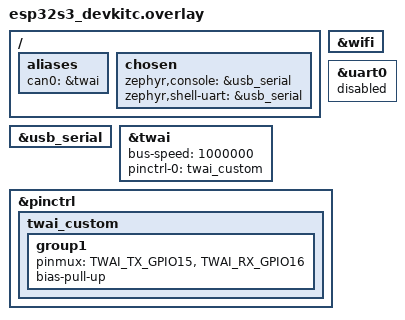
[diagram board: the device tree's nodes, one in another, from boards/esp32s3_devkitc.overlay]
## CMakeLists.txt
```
cmake_minimum_required(VERSION 3.20.0)

find_package(Zephyr REQUIRED HINTS $ENV{ZEPHYR_BASE})
project(can_dongle)

if(EXISTS "${CMAKE_CURRENT_SOURCE_DIR}/src/wifi_secrets.h")
  target_compile_definitions(app PRIVATE DONGLE_USE_LOCAL_WIFI_SECRETS=1)
endif()

target_sources(app PRIVATE
  src/main.c
  src/command_handler.c
  src/command_policy.c
  src/motor_status_policy.c
  src/telemetry.c
  src/telemetry_policy.c
  src/sdo_transport.c
  src/udp_comm.c
  src/can_raw.c
  src/canopen_basic.c
  src/json_protocol.c
  src/watchdog.c
)
```

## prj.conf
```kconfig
# ---- Early Console (调试必需) ----
CONFIG_EARLY_CONSOLE=y
CONFIG_CONSOLE=y
CONFIG_UART_CONSOLE=y

# ---- Wi-Fi + Networking ----
CONFIG_WIFI=y
CONFIG_WIFI_LOG_LEVEL_DBG=n
CONFIG_NETWORKING=y
CONFIG_NET_L2_ETHERNET=y
CONFIG_NET_UDP=y
CONFIG_NET_SOCKETS=y
CONFIG_NET_IPV4=y
CONFIG_NET_IPV6=n
CONFIG_NET_CONFIG_AUTO_INIT=n

# ---- DHCP Server (AP 模式下给客户端分配 IP) ----
CONFIG_NET_DHCPV4_SERVER=y
CONFIG_NET_DHCPV4_SERVER_LOG_LEVEL_DBG=n

# ---- CAN ----
CONFIG_CAN=y
# CONFIG_CAN_AUTO_BUS_OFF_RECOVERY removed in Zephyr 4.4

# ---- Logging ----
CONFIG_LOG=y
CONFIG_LOG_DEFAULT_LEVEL=3
CONFIG_LOG_PRINTK=y

# ---- JSON support ----
CONFIG_JSON_LIBRARY=y

# ---- Memory ----
CONFIG_MAIN_STACK_SIZE=8192
CONFIG_HEAP_MEM_POOL_SIZE=65536

# ---- Shell (debug only, disable for production) ----
CONFIG_SHELL=n

# ---- Assert ----
CONFIG_ASSERT=y

# ---- Explicit main-thread scheduling ----
CONFIG_MAIN_THREAD_PRIORITY=5
CONFIG_SYSTEM_WORKQUEUE_PRIORITY=1
```

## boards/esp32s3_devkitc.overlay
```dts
/ {
	aliases {
		can0 = &twai;
	};

	chosen {
		zephyr,console = &usb_serial;
		zephyr,shell-uart = &usb_serial;
	};
};

&wifi {
	status = "okay";
};

&usb_serial {
	status = "okay";
};

&uart0 {
	status = "disabled";
};

&twai {
	status = "okay";
	bus-speed = <1000000>;
	/* TX=GPIO15 确认可用, RX=GPIO16 + 内部上拉 */
	pinctrl-0 = <&twai_custom>;
	pinctrl-names = "default";
};

&pinctrl {
	twai_custom: twai_custom {
		group1 {
			pinmux = <TWAI_TX_GPIO15>,
				 <TWAI_RX_GPIO16>;
			bias-pull-up;
		};
	};
};
```

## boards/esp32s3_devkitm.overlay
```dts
/ {
	aliases {
		can0 = &twai;
	};

	chosen {
		zephyr,console = &usb_serial;
		zephyr,shell-uart = &usb_serial;
	};
};

&wifi {
	status = "okay";
};

&usb_serial {
	status = "okay";
};

&uart0 {
	status = "disabled";
};

&twai {
	status = "okay";
	bus-speed = <1000000>;
	pinctrl-0 = <&twai_default>;
	pinctrl-names = "default";
};
```

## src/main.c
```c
#include <zephyr/kernel.h>
#include <zephyr/logging/log.h>

#include "udp_comm.h"
#include "can_raw.h"
#include "json_protocol.h"
#include "watchdog.h"
#include "motor_state.h"
#include "command_handler.h"
#include "telemetry.h"
#include "sdo_transport.h"

LOG_MODULE_REGISTER(main, LOG_LEVEL_INF);

#define MAIN_LOOP_DELAY_MS 10
#define UDP_RECEIVE_TIMEOUT_MS 10
#define MAX_UDP_MESSAGES_PER_LOOP 16
#define MAX_CAN_FRAMES_PER_LOOP 8

struct motor_state g_motor = {
	.drive_status_word = 0x0040,
	.mode = MODE_PROFILE_VELOCITY,
};
bool g_motor_enabled;
bool g_profile_configured;
int32_t g_target_speed = 50000;
uint8_t g_active_node = DEFAULT_NODE;

static void forward_can_frames(void)
{
	can_frame_t frame;
	char buffer[256];
	for (int count = 0;
	     count < MAX_CAN_FRAMES_PER_LOOP && can_recv(&frame) == 1;
	     count++) {
		int length = json_build_can_log(buffer, sizeof(buffer),
						frame.id, frame.data, frame.dlc);
		udp_send(buffer, length);
	}
}

static void handle_udp_messages(char *buffer, int buffer_size)
{
	int timeout_ms = UDP_RECEIVE_TIMEOUT_MS;

	for (int count = 0; count < MAX_UDP_MESSAGES_PER_LOOP; count++) {
		int length = udp_recv(buffer, buffer_size, timeout_ms);
		if (length <= 0) break;

		parsed_cmd_t command;
		if (cmd_json_parse(buffer, length, &command))
			command_handle(&command);

		timeout_ms = 0;
	}
}

int main(void)
{
	wdg_init();
	int ret = udp_init();
	if (ret < 0) LOG_ERR("UDP init failed: %d", ret);
	ret = can_init();
	if (ret < 0) LOG_WRN("CAN init failed: %d", ret);
	else can_diag();

	char receive_buffer[2048];
	while (1) {
		handle_udp_messages(receive_buffer, sizeof(receive_buffer));
		if (wdg_check())
			command_handle_watchdog_timeout();
		forward_can_frames();
		telemetry_send();
		k_msleep(MAIN_LOOP_DELAY_MS);
	}
	return 0;
}
```

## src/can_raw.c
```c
/*
 * can_raw.c - CAN 原始帧收发模块实现
 *
 * 使用 Zephyr CAN 驱动。硬件假设:
 *   - ESP32-S3 内部 TWAI 控制器
 *   - 外部 TJA1050 收发器
 *   - RX: GPIO16, TX: GPIO15 (在 overlay 中定义)
 */

#include "can_raw.h"

#include <stdio.h>
#include <string.h>
#include <zephyr/kernel.h>
#include <zephyr/device.h>
#include <zephyr/drivers/can.h>
#include <zephyr/logging/log.h>

LOG_MODULE_REGISTER(can_raw, LOG_LEVEL_INF);

/* ---- 配置 ---- */
#define CAN_BAUDRATE		1000000

/* ---- 消息队列: 缓冲接收到的 CAN 帧 ---- */
CAN_MSGQ_DEFINE(can_rx_msgq, 16);

/* ---- 状态 ---- */
static const struct device *can_dev = NULL;
static bool initialized = false;
static int rx_filter_id = -1;
static K_SEM_DEFINE(tx_done_sem, 0, 1);
static int tx_done_error;

static void log_can_state(const char *where)
{
	enum can_state state;
	struct can_bus_err_cnt err_cnt;
	int ret;

	if (!can_dev) {
		return;
	}

	ret = can_get_state(can_dev, &state, &err_cnt);
	if (ret < 0) {
		LOG_WRN("%s: failed to get CAN state: %d", where, ret);
		return;
	}

	LOG_WRN("%s: CAN state=%d tx_err=%u rx_err=%u",
		where, state, err_cnt.tx_err_cnt, err_cnt.rx_err_cnt);
}

static int can_restart_if_needed(const char *where)
{
	enum can_state state;
	struct can_bus_err_cnt err_cnt;
	int ret;

	if (!can_dev) {
		return -ENODEV;
	}

	ret = can_get_state(can_dev, &state, &err_cnt);
	if (ret < 0) {
		return ret;
	}

	if (state != CAN_STATE_ERROR_PASSIVE &&
	    state != CAN_STATE_BUS_OFF &&
	    state != CAN_STATE_STOPPED) {
		return 0;
	}

	LOG_WRN("%s: restarting CAN controller state=%d tx_err=%u rx_err=%u",
		where, state, err_cnt.tx_err_cnt, err_cnt.rx_err_cnt);

	(void)can_stop(can_dev);
	k_msleep(20);
	ret = can_start(can_dev);
	if (ret < 0) {
		LOG_ERR("%s: CAN restart failed: %d", where, ret);
		return ret;
	}

	k_msleep(20);
	log_can_state("after restart");
	return 0;
}

int can_force_recover(const char *where)
{
	can_frame_t dropped;
	int ret;

	if (!can_dev || !initialized) {
		return -ENODEV;
	}

	LOG_INF("%s: forcing CAN controller recovery", where ? where : "can_force_recover");
	(void)can_stop(can_dev);
	k_msleep(20);
	ret = can_start(can_dev);
	if (ret < 0) {
		LOG_ERR("%s: CAN recovery start failed: %d",
			where ? where : "can_recover", ret);
		return ret;
	}

	while (can_recv(&dropped) == 1) {
		/* Drop stale SDO/heartbeat frames after a controller restart. */
	}
	k_msleep(50);
	log_can_state("after forced recovery");
	return 0;
}

/* 公开诊断函数：打印 CAN 控制器状态和错误计数 */
void can_diag(void)
{
	if (!can_dev) {
		LOG_ERR("CAN diag: device not ready");
		return;
	}

	enum can_state state;
	struct can_bus_err_cnt err_cnt;
	int ret = can_get_state(can_dev, &state, &err_cnt);
	if (ret < 0) {
		LOG_ERR("CAN diag: get_state failed: %d", ret);
		return;
	}

	const char *state_str;
	switch (state) {
	case CAN_STATE_ERROR_ACTIVE:  state_str = "Error-Active (OK)"; break;
	case CAN_STATE_ERROR_WARNING: state_str = "Error-Warning"; break;
	case CAN_STATE_ERROR_PASSIVE: state_str = "Error-Passive"; break;
	case CAN_STATE_BUS_OFF:       state_str = "Bus-Off!"; break;
	case CAN_STATE_STOPPED:       state_str = "Stopped"; break;
	default:                      state_str = "Unknown"; break;
	}

	LOG_INF("=== CAN Diagnostics ===");
	LOG_INF("  State: %s", state_str);
	LOG_INF("  TX errors: %u, RX errors: %u", err_cnt.tx_err_cnt, err_cnt.rx_err_cnt);
	if (err_cnt.tx_err_cnt > 0) {
		LOG_WRN("  TX errors indicate CAN bus wiring issue or no device on bus");
	}
	if (state == CAN_STATE_BUS_OFF) {
		LOG_ERR("  Bus-Off! Check CANH/CANL wiring and termination resistors");
	}
	LOG_INF("========================");
}

static void can_tx_done(const struct device *dev, int error, void *user_data)
{
	ARG_UNUSED(dev);
	ARG_UNUSED(user_data);
	tx_done_error = error;
	if (error != 0) {
		LOG_WRN("CAN TX completed with error: %d", error);
	}
	k_sem_give(&tx_done_sem);
}

int can_init(void)
{
	int ret;

	/* 获取 CAN 设备 */
	can_dev = DEVICE_DT_GET(DT_ALIAS(can0));
	if (!device_is_ready(can_dev)) {
		LOG_ERR("CAN device not ready");
		return -ENODEV;
	}
	LOG_INF("CAN device: %s", can_dev->name);

	/* 配置位时序: 1000 kbps */
	ret = can_set_bitrate(can_dev, CAN_BAUDRATE);
	if (ret < 0) {
		LOG_ERR("Failed to set CAN bitrate: %d", ret);
		return ret;
	}

	/* 设置滤波: 接收所有帧，放入消息队列 */
	const struct can_filter all_filter = {
		.flags = 0,  /* 匹配所有帧 (标准和扩展, 数据和远程) */
		.id = 0,
		.mask = 0,
	};
	rx_filter_id = can_add_rx_filter_msgq(can_dev, &can_rx_msgq, &all_filter);
	if (rx_filter_id < 0) {
		LOG_ERR("Failed to add CAN filter: %d", rx_filter_id);
		return rx_filter_id;
	}

	/* 启动 CAN 控制器 */
	ret = can_start(can_dev);
	if (ret < 0) {
		LOG_ERR("Failed to start CAN: %d", ret);
		return ret;
	}

	initialized = true;
	LOG_INF("CAN initialized at %d kbps", CAN_BAUDRATE / 1000);
	return 0;
}

int can_recv(can_frame_t *frame)
{
	struct can_frame z_frame;

	if (!initialized) return -EAGAIN;

	/* 非阻塞从消息队列读取 CAN 帧 */
	int ret = k_msgq_get(&can_rx_msgq, &z_frame, K_NO_WAIT);
	if (ret == -ENOMSG) {
		return 0; /* 无可用帧 */
	}
	if (ret < 0) {
		return ret;
	}

	/* 转换为我们的帧结构 */
	frame->id = z_frame.id;
	frame->dlc = (uint8_t)can_dlc_to_bytes(z_frame.dlc);
	memcpy(frame->data, z_frame.data, MIN(frame->dlc, 8));
	frame->ext = (z_frame.flags & CAN_FRAME_IDE) != 0;
	frame->rtr = (z_frame.flags & CAN_FRAME_RTR) != 0;

	return 1;
}

int can_raw_send(const can_frame_t *frame)
{
	int ret;
	struct can_frame z_frame;

	if (!initialized) return -EAGAIN;

	memset(&z_frame, 0, sizeof(z_frame));
	z_frame.id = frame->id;
	z_frame.dlc = can_bytes_to_dlc(frame->dlc);
	memcpy(z_frame.data, frame->data, MIN(frame->dlc, 8));

	if (frame->ext) z_frame.flags |= CAN_FRAME_IDE;
	if (frame->rtr) z_frame.flags |= CAN_FRAME_RTR;

	(void)can_restart_if_needed("before tx");

	while (k_sem_take(&tx_done_sem, K_NO_WAIT) == 0) {
		/* Drain stale completion signals before submitting a new frame. */
	}
	tx_done_error = 0;

	ret = can_send(can_dev, &z_frame, K_MSEC(5), can_tx_done, NULL);
	if (ret < 0) {
		LOG_WRN("CAN TX submit failed id=0x%X ret=%d", frame->id, ret);
		log_can_state("tx submit failed");
		(void)can_restart_if_needed("after tx submit failed");
		return ret;
	}

	ret = k_sem_take(&tx_done_sem, K_MSEC(30));
	if (ret < 0) {
		LOG_WRN("CAN TX timeout/no ACK id=0x%X", frame->id);
		log_can_state("tx timeout");
		(void)can_restart_if_needed("after tx timeout");
		return -ETIMEDOUT;
	}

	if (tx_done_error != 0) {
		LOG_WRN("CAN TX done error id=0x%X err=%d",
			frame->id, tx_done_error);
		log_can_state("tx done error");
		(void)can_restart_if_needed("after tx done error");
		return tx_done_error;
	}

	return 0;
}

int can_frame_to_string(const can_frame_t *frame, char *buf, int buf_size)
{
	int pos = 0;
	pos += snprintf(buf + pos, buf_size - pos,
			"ID:0x%X EXT:%d DLC:%d DATA:",
			frame->id, frame->ext ? 1 : 0, frame->dlc);
	for (int i = 0; i < frame->dlc && i < 8; i++) {
		pos += snprintf(buf + pos, buf_size - pos,
				"%s%02X", (i > 0 ? " " : ""), frame->data[i]);
	}
	return pos;
}
```

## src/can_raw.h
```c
/*
 * can_raw.h - CAN 原始帧收发模块
 *
 * 负责:
 *   - CAN 控制器初始化 (1000 kbps)
 *   - 接收/发送 CAN 原始帧
 *   - 将 CAN 帧格式化为可读字符串
 */

#pragma once

#include <stdint.h>
#include <stdbool.h>
#include <stddef.h>

/* CAN 帧结构 */
typedef struct {
	uint32_t id;       /* 标准帧 11 位 或 扩展帧 29 位 */
	uint8_t  data[8];  /* 数据字节 */
	uint8_t  dlc;      /* 数据长度 (0-8) */
	bool     ext;      /* true = 扩展帧 */
	bool     rtr;      /* true = 远程帧 */
} can_frame_t;

/**
 * 初始化 CAN 控制器。
 * 波特率: 1000000
 * 成功返回 0，失败返回负值。
 */
int can_init(void);

/**
 * 非阻塞接收一个 CAN 帧。
 * @param frame 输出帧
 * @return 1: 成功接收到帧; 0: 没有可用帧; <0: 错误
 */
int can_recv(can_frame_t *frame);

/**
 * 发送一个 CAN 帧。
 * @return 0: 成功; <0: 错误
 */
int can_raw_send(const can_frame_t *frame);

/**
 * 将 CAN 帧格式化为可读字符串。
 * 例: "ID:0x123 EXT:0 DLC:8 DATA:01 02 03 04 05 06 07 08"
 * @return 写入的字节数
 */
int can_frame_to_string(const can_frame_t *frame, char *buf, int buf_size);

/**
 * 诊断 CAN 总线状态：打印状态和错误计数器。
 * 用于判断 CAN 引脚是否连接正确。
 */
void can_diag(void);

/**
 * Force a CAN controller restart and clear any queued RX frames.
 * Useful after ESP32 reboot or a transient bus error before starting
 * a CANopen command sequence.
 */
int can_force_recover(const char *where);
```

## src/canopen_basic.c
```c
#include "canopen_basic.h"
#include "can_raw.h"
#include "sdo_transport.h"

#include <zephyr/kernel.h>
#include <zephyr/logging/log.h>

LOG_MODULE_REGISTER(canopen_basic, LOG_LEVEL_INF);

int co_basic_enable(uint8_t node)
{
	int ret;
	LOG_INF("=== CANopen enable node=%u ===", node);
	(void)can_force_recover("before CANopen enable");
	(void)nmt_start(node);
	k_msleep(100);

	ret = sdo_write(node, OD_MODE_OPERATION, 0, MODE_PROFILE_VELOCITY, 1);
	if (ret < 0) {
		LOG_WRN("Mode write failed node=%u ret=%d, resetting communication", node, ret);
		(void)can_force_recover("retry after mode write failed");
		(void)nmt_reset_comm(node);
		k_msleep(1200);
		(void)nmt_start(node);
		k_msleep(300);
		ret = sdo_write(node, OD_MODE_OPERATION, 0, MODE_PROFILE_VELOCITY, 1);
		if (ret < 0) return ret;
	}

	(void)sdo_write(node, OD_CONTROL_WORD, 0, CW_FAULT_RESET, 2);
	k_msleep(100);
	ret = sdo_write(node, OD_CONTROL_WORD, 0, CW_SHUTDOWN, 2);
	if (ret < 0) return ret;
	k_msleep(200);
	ret = sdo_write(node, OD_CONTROL_WORD, 0, CW_SWITCH_ON, 2);
	if (ret < 0) return ret;
	k_msleep(200);
	ret = sdo_write(node, OD_CONTROL_WORD, 0, CW_ENABLE_OPERATION, 2);
	if (ret < 0) return ret;
	k_msleep(200);

	uint16_t status;
	ret = co_read_status_word(node, &status);
	if (ret == 0) LOG_INF("Motor enabled status=0x%04X", status);
	return 0;
}

int co_basic_disable(uint8_t node)
{
	LOG_INF("Disable motor node=%u", node);
	(void)sdo_write(node, OD_CONTROL_WORD, 0, CW_QUICK_STOP, 2);
	k_msleep(100);
	int ret = sdo_write(node, OD_CONTROL_WORD, 0, CW_DISABLE_VOLTAGE, 2);
	k_msleep(100);
	if (ret == 0) LOG_INF("Motor disabled node=%u", node);
	return ret;
}

int co_basic_estop(uint8_t node)
{
	LOG_WRN("E-STOP node=%u", node);
	(void)sdo_write(node, OD_CONTROL_WORD, 0, CW_QUICK_STOP, 2);
	k_msleep(20);
	return sdo_write(node, OD_CONTROL_WORD, 0, CW_DISABLE_VOLTAGE, 2);
}

int co_init_profile(uint8_t node)
{
	int ret = sdo_write(node, OD_MODE_OPERATION, 0, MODE_PROFILE_VELOCITY, 1);
	if (ret < 0) return ret;
	k_msleep(200);
	ret = sdo_write(node, OD_PROFILE_VELOCITY, 0, DEFAULT_PROFILE_VELOCITY, 4);
	if (ret < 0) return ret;
	ret = sdo_write(node, OD_PROFILE_ACCELERATION, 0, DEFAULT_PROFILE_ACCELERATION, 4);
	if (ret < 0) return ret;
	return sdo_write(node, OD_PROFILE_DECELERATION, 0, DEFAULT_PROFILE_DECELERATION, 4);
}

int co_basic_jog(uint8_t node, int32_t velocity)
{
	return sdo_write(node, OD_TARGET_VELOCITY, 0, (uint32_t)velocity, 4);
}

int co_move_to_position(uint8_t node, int32_t position, int32_t speed)
{
	uint32_t velocity = speed < 0 ? (uint32_t)-speed : (uint32_t)speed;
	if (velocity == 0) velocity = DEFAULT_PROFILE_VELOCITY;
	(void)nmt_start(node);
	int ret = sdo_write(node, OD_MODE_OPERATION, 0, MODE_PROFILE_POSITION, 1);
	if (ret < 0) return ret;
	ret = sdo_write(node, OD_PROFILE_VELOCITY, 0, velocity, 4);
	if (ret < 0) return ret;
	ret = sdo_write(node, OD_TARGET_POSITION, 0, (uint32_t)position, 4);
	if (ret < 0) return ret;
	ret = sdo_write(node, OD_CONTROL_WORD, 0, CW_ENABLE_OPERATION, 2);
	if (ret < 0) return ret;
	return sdo_write(node, OD_CONTROL_WORD, 0, CW_CHANGE_IMM, 2);
}

int co_basic_stop(uint8_t node)
{
	(void)sdo_write(node, OD_TARGET_VELOCITY, 0, 0, 4);
	return sdo_write(node, OD_CONTROL_WORD, 0, CW_QUICK_STOP, 2);
}

int co_read_status_word(uint8_t node, uint16_t *value)
{
	return sdo_read_u16(node, OD_STATUS_WORD, 0, value);
}

int co_read_actual_velocity(uint8_t node, int32_t *value)
{
	return sdo_read_i32(node, OD_ACTUAL_VELOCITY, 0, value);
}

int co_read_actual_current(uint8_t node, int32_t *value)
{
	return sdo_read_i32(node, OD_CURRENT_ACTUAL, 0, value);
}

int co_read_dc_link_voltage(uint8_t node, uint32_t *value)
{
	return sdo_read_u32(node, OD_DC_LINK_VOLTAGE, 0, value);
}

int co_read_actual_torque(uint8_t node, int16_t *value)
{
	return sdo_read_i16(node, OD_TORQUE_ACTUAL, 0, value);
}

int co_read_actual_position(uint8_t node, int32_t *value)
{
	return sdo_read_i32(node, OD_ACTUAL_POSITION, 0, value);
}
```

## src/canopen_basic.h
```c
#pragma once

#include <stdint.h>
#include "sdo_transport.h"

#define co_sdo_write sdo_write

int co_basic_enable(uint8_t node);
int co_basic_disable(uint8_t node);
int co_basic_estop(uint8_t node);
int co_init_profile(uint8_t node);
int co_basic_jog(uint8_t node, int32_t velocity);
int co_move_to_position(uint8_t node, int32_t position, int32_t speed);
int co_basic_stop(uint8_t node);

int co_read_status_word(uint8_t node, uint16_t *value);
int co_read_actual_velocity(uint8_t node, int32_t *value);
int co_read_actual_current(uint8_t node, int32_t *value);
int co_read_dc_link_voltage(uint8_t node, uint32_t *value);
int co_read_actual_torque(uint8_t node, int16_t *value);
int co_read_actual_position(uint8_t node, int32_t *value);
```

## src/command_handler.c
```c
/*
 * command_handler.c - UDP 命令解析与分发
 */

#include "command_handler.h"
#include "command_policy.h"
#include "motor_state.h"
#include "motor_status_policy.h"
#include "canopen_basic.h"
#include "json_protocol.h"
#include "telemetry.h"
#include "udp_comm.h"
#include "watchdog.h"

#include <errno.h>
#include <stdio.h>
#include <zephyr/logging/log.h>

LOG_MODULE_REGISTER(cmd_handler, LOG_LEVEL_INF);

static void invalidate_commanded_fields(uint32_t fields)
{
	g_motor.valid_mask &= ~fields;
	g_motor.fresh_mask &= ~fields;
}

void command_handle_watchdog_timeout(void)
{
	if (!g_motor_enabled) {
		return;
	}

	LOG_WRN("Heartbeat watchdog stopping active node=%u", g_active_node);
	int ret = co_basic_estop(g_active_node);
	g_motor_enabled = false;
	g_profile_configured = false;
	g_motor.estop_latched = motor_estop_should_latch(ret);
	invalidate_commanded_fields(MOTOR_FIELD_BIT(MOTOR_FIELD_SPEED) |
				    MOTOR_FIELD_BIT(MOTOR_FIELD_STATUS));
	if (ret < 0) {
		LOG_ERR("Watchdog safety stop failed node=%u ret=%d",
			g_active_node, ret);
	}
}

void command_handle(const parsed_cmd_t *cmd)
{
	if (cmd == NULL) {
		return;
	}

	char ack_buf[512];
	int ack_len;
	const char *client_ip = udp_client_ip();

	uint8_t resolved_node = command_resolve_node(cmd->cmd, cmd->node,
						     g_active_node);
	if (command_updates_active_node(cmd->cmd)) {
		if (resolved_node != g_active_node) {
			g_profile_configured = false;
			telemetry_reset();
		}
		g_active_node = resolved_node;
	}

	/* estop — always allowed, same CAN ops as disable, different status */
	if (cmd->cmd == CMD_ESTOP) {
		LOG_WRN("ESTOP from %s packet_node=%d active_node=%u",
			client_ip, cmd->node, resolved_node);
		int ret = co_basic_estop(resolved_node);
		g_motor_enabled = false;
		g_profile_configured = false;
		g_motor.estop_latched = motor_estop_should_latch(ret);
		invalidate_commanded_fields(MOTOR_FIELD_BIT(MOTOR_FIELD_SPEED) |
					    MOTOR_FIELD_BIT(MOTOR_FIELD_CURRENT) |
					    MOTOR_FIELD_BIT(MOTOR_FIELD_STATUS));
		ack_len = json_build_ack(ack_buf, sizeof(ack_buf), cmd->seq,
					 ret == 0 ? "ok" : "error",
					 ret == 0 ? "emergency disable latched"
						  : "emergency disable failed",
					 resolved_node);
		udp_send(ack_buf, ack_len);
		return;
	}

	/* heartbeat — always allowed */
	if (cmd->cmd == CMD_HEARTBEAT) {
		wdg_feed();
		ack_len = json_build_ack(ack_buf, sizeof(ack_buf), cmd->seq,
					 "ok", "alive", resolved_node);
		udp_send(ack_buf, ack_len);
		return;
	}

	/* watchdog safety gate */
	if (wdg_is_safe() &&
	    (cmd->cmd == CMD_ENABLE || cmd->cmd == CMD_DISABLE ||
	     cmd->cmd == CMD_JOG_START || cmd->cmd == CMD_JOG_STOP ||
	     cmd->cmd == CMD_MOVE_POSITION)) {
		ack_len = json_build_ack(ack_buf, sizeof(ack_buf), cmd->seq,
					 "error",
					 "watchdog timeout — motor control blocked",
					 resolved_node);
		udp_send(ack_buf, ack_len);
		LOG_WRN("Command blocked by watchdog (cmd=%d)", cmd->cmd);
		return;
	}

	switch (cmd->cmd) {
	case CMD_ENABLE:
		LOG_INF("ENABLE node=%u from %s", resolved_node, client_ip);
		if (co_basic_enable(resolved_node) == 0) {
			g_motor_enabled = true;
			g_motor.alive = true;
			g_motor.estop_latched = false;
			uint16_t status;
			if (co_read_status_word(resolved_node, &status) == 0) {
				g_motor.drive_status_word = status;
				g_motor.drive_fault =
					motor_status_word_has_fault(status);
			}
			ack_len = json_build_ack(ack_buf, sizeof(ack_buf), cmd->seq,
						 "ok", "motor enabled", resolved_node);
		} else {
			ack_len = json_build_ack(ack_buf, sizeof(ack_buf), cmd->seq,
						 "error", "CAN enable failed", resolved_node);
		}
		udp_send(ack_buf, ack_len);
		break;

	case CMD_DISABLE:
		LOG_INF("DISABLE node=%u from %s", resolved_node, client_ip);
		{
			int ret = co_basic_disable(resolved_node);
			if (ret == 0) {
				g_motor_enabled = false;
				g_profile_configured = false;
				invalidate_commanded_fields(
					MOTOR_FIELD_BIT(MOTOR_FIELD_SPEED) |
					MOTOR_FIELD_BIT(MOTOR_FIELD_STATUS));
			}
			ack_len = json_build_ack(ack_buf, sizeof(ack_buf), cmd->seq,
						 ret == 0 ? "ok" : "error",
						 ret == 0 ? "motor disabled"
							  : "motor disable failed",
						 resolved_node);
		}
		udp_send(ack_buf, ack_len);
		break;

	case CMD_JOG_START:
		LOG_INF("JOG_START node=%u dir=%s speed=%d from %s",
			resolved_node, cmd->direction, cmd->speed, client_ip);
		if (cmd->speed > 0) {
			g_target_speed = cmd->speed;
		}
		{
			int vel = (cmd->direction[0] == 'c' && cmd->direction[1] == 'c')
				  ? -g_target_speed : g_target_speed;
			int ret = g_motor_enabled ? 0 : -EPERM;
			if (ret == 0 && !g_profile_configured) {
				ret = co_init_profile(resolved_node);
				if (ret == 0) {
					g_profile_configured = true;
				}
			}
			if (ret == 0) {
				ret = co_basic_jog(resolved_node, vel);
			}
			if (ret == 0) {
				g_motor.speed = vel;
			}
			ack_len = json_build_ack(ack_buf, sizeof(ack_buf), cmd->seq,
						 ret == 0 ? "ok" : "error",
						 ret == 0 ? "jog started"
							  : (ret == -EPERM
							     ? "motor not enabled"
							     : "jog start failed"),
						 resolved_node);
		}
		udp_send(ack_buf, ack_len);
		break;

	case CMD_SET_SPEED:
		if (cmd->speed < 1 || cmd->speed > 300000) {
			ack_len = json_build_ack(ack_buf, sizeof(ack_buf), cmd->seq,
						 "error", "speed range 1-300000", resolved_node);
		} else {
			g_target_speed = cmd->speed;
			ack_len = json_build_ack(ack_buf, sizeof(ack_buf), cmd->seq,
						 "ok", "speed updated", resolved_node);
		}
		udp_send(ack_buf, ack_len);
		break;

	case CMD_MOVE_POSITION: {
		LOG_INF("MOVE_POSITION node=%u pos=%d speed=%d from %s",
			resolved_node, cmd->position, cmd->speed, client_ip);
		int move_speed = cmd->speed > 0 ? cmd->speed : g_target_speed;
		if (co_move_to_position(resolved_node, (int32_t)cmd->position,
					move_speed) == 0) {
			g_motor.alive = true;
			ack_len = json_build_ack(ack_buf, sizeof(ack_buf), cmd->seq,
						 "ok", "position move started", resolved_node);
		} else {
			ack_len = json_build_ack(ack_buf, sizeof(ack_buf), cmd->seq,
						 "error", "position move failed", resolved_node);
		}
		udp_send(ack_buf, ack_len);
		break;
	}

	case CMD_JOG_STOP:
		LOG_INF("JOG_STOP node=%u from %s", resolved_node, client_ip);
		{
			int ret = co_basic_stop(resolved_node);
			if (ret == 0) {
				g_motor.speed = 0;
			}
			ack_len = json_build_ack(ack_buf, sizeof(ack_buf), cmd->seq,
						 ret == 0 ? "ok" : "error",
						 ret == 0 ? "jog stopped"
							  : "jog stop failed",
						 resolved_node);
		}
		udp_send(ack_buf, ack_len);
		break;

	case CMD_SDO_READ: {
		LOG_INF("SDO_READ node=%u idx=0x%04X sub=%d from %s",
			resolved_node, cmd->index, cmd->sub, client_ip);
		uint32_t value;
		int ret = sdo_read_u32(resolved_node, (uint16_t)cmd->index,
				       (uint8_t)cmd->sub, &value);
		char sdo_buf[256];
		if (ret == 0) {
			int sdo_len = snprintf(sdo_buf, sizeof(sdo_buf),
				"{\"cmd\":\"sdo_read_result\",\"seq\":%d,\"ts\":0,"
				"\"payload\":{\"index\":%d,\"sub\":%d,"
				"\"data\":\"0x%08X\",\"node\":%u}}",
				cmd->seq, cmd->index, cmd->sub, value, resolved_node);
			udp_send(sdo_buf, sdo_len);
		} else {
			ack_len = json_build_ack(ack_buf, sizeof(ack_buf), cmd->seq,
						 "error", "sdo read failed",
						 resolved_node);
			udp_send(ack_buf, ack_len);
		}
		break;
	}

	case CMD_SDO_WRITE:
		LOG_INF("SDO_WRITE node=%u idx=0x%04X sub=%d data=%d from %s",
			resolved_node, cmd->index, cmd->sub, cmd->data, client_ip);
		{
			uint8_t size = 4;
			if (cmd->index == 0x6060) size = 1;
			else if (cmd->index == 0x6040 || cmd->index == 0x6041 ||
				 cmd->index == 0x603F) size = 2;
			int ret = co_sdo_write(resolved_node,
					       (uint16_t)cmd->index,
					       (uint8_t)cmd->sub,
					       (uint32_t)cmd->data, size);
			ack_len = json_build_ack(ack_buf, sizeof(ack_buf), cmd->seq,
						 ret == 0 ? "ok" : "error",
						 ret == 0 ? "sdo write ok" : "sdo write failed",
						 resolved_node);
		}
		udp_send(ack_buf, ack_len);
		break;

	case CMD_OTA_START:
		LOG_INF("OTA_START size=%d md5=%s", cmd->ota_size, cmd->md5);
		ack_len = snprintf(ack_buf, sizeof(ack_buf),
			"{\"cmd\":\"ota_status\",\"seq\":%d,\"ts\":0,"
			"\"payload\":{\"state\":\"ready\",\"msg\":\"ready\"}}",
			cmd->seq);
		udp_send(ack_buf, ack_len);
		break;

	case CMD_OTA_CHUNK:
		ack_len = json_build_ack(ack_buf, sizeof(ack_buf), cmd->seq,
					 "ok", "chunk received", 0);
		udp_send(ack_buf, ack_len);
		break;

	case CMD_OTA_VERIFY:
		ack_len = snprintf(ack_buf, sizeof(ack_buf),
			"{\"cmd\":\"ota_status\",\"seq\":%d,\"ts\":0,"
			"\"payload\":{\"state\":\"done\",\"msg\":\"MD5 OK\"}}",
			cmd->seq);
		udp_send(ack_buf, ack_len);
		break;

	case CMD_OTA_FLASH:
		ack_len = snprintf(ack_buf, sizeof(ack_buf),
			"{\"cmd\":\"ota_status\",\"seq\":%d,\"ts\":0,"
			"\"payload\":{\"state\":\"done\",\"msg\":\"flash done\"}}",
			cmd->seq);
		udp_send(ack_buf, ack_len);
		break;

	case CMD_UNKNOWN:
	default:
		LOG_WRN("Unknown cmd from %s", client_ip);
		ack_len = json_build_ack(ack_buf, sizeof(ack_buf), cmd->seq,
					 "error", "unknown command", 0);
		udp_send(ack_buf, ack_len);
		break;
	}
}
```

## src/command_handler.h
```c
/*
 * command_handler.h - UDP 命令解析与分发
 */

#pragma once

#include "json_protocol.h"

/** 在主循环中每次收到合法 JSON 命令后调用。 */
void command_handle(const parsed_cmd_t *cmd);

/** RGB30 心跳超时后执行一次主动安全失能。 */
void command_handle_watchdog_timeout(void);
```

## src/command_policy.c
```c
#include "command_policy.h"

uint8_t command_resolve_node(cmd_type_t command, int packet_node,
			     uint8_t active_node)
{
	if (command == CMD_HEARTBEAT || command == CMD_ESTOP) {
		return active_node;
	}
	return packet_node >= 1 && packet_node <= 127
		? (uint8_t)packet_node : active_node;
}

bool command_updates_active_node(cmd_type_t command)
{
	switch (command) {
	case CMD_ENABLE:
	case CMD_DISABLE:
	case CMD_JOG_START:
	case CMD_JOG_STOP:
	case CMD_SDO_READ:
	case CMD_SDO_WRITE:
	case CMD_SET_SPEED:
	case CMD_MOVE_POSITION:
		return true;
	case CMD_HEARTBEAT:
	case CMD_ESTOP:
	case CMD_OTA_START:
	case CMD_OTA_CHUNK:
	case CMD_OTA_VERIFY:
	case CMD_OTA_FLASH:
	case CMD_UNKNOWN:
	default:
		return false;
	}
}
```

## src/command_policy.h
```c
#pragma once

#include <stdint.h>
#include "json_protocol.h"

uint8_t command_resolve_node(cmd_type_t command, int packet_node,
			     uint8_t active_node);
bool command_updates_active_node(cmd_type_t command);
```

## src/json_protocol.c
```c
/*
 * json_protocol.c - JSON 协议解析与构建实现
 */

#include "json_protocol.h"

#include <stdio.h>
#include <string.h>
#include <stdlib.h>
#include <ctype.h>

static const char *skip_ws(const char *p)
{
	while (*p && isspace((unsigned char)*p)) p++;
	return p;
}

static const char *json_find_value(const char *s, const char *key)
{
	char search[64];
	int n = snprintf(search, sizeof(search), "\"%s\"", key);
	const char *p = strstr(s, search);
	if (!p) return NULL;
	p += n;
	p = skip_ws(p);
	if (*p != ':') return NULL;
	p++;
	return skip_ws(p);
}

static bool json_get_string(const char *s, const char *key, char *val, int val_size)
{
	const char *p = json_find_value(s, key);
	if (!p || *p != '"') return false;
	p++;
	int i;
	for (i = 0; i < val_size - 1 && *p && *p != '"'; i++, p++)
		val[i] = *p;
	val[i] = '\0';
	return true;
}

static bool json_get_int(const char *s, const char *key, int *val)
{
	const char *p = json_find_value(s, key);
	if (!p) return false;
	if (*p == '"') p++;
	*val = atoi(p);
	return true;
}

static int scale_float(float value, int scale)
{
	float scaled = value * (float)scale;
	return (int)(scaled + (scaled >= 0.0f ? 0.5f : -0.5f));
}

static void format_fixed(char *buf, size_t buf_size, float value, int decimals)
{
	int scale = (decimals == 1) ? 10 : 100;
	int scaled = scale_float(value, scale);
	int abs_scaled = scaled < 0 ? -scaled : scaled;
	const char *sign = scaled < 0 ? "-" : "";
	int whole = abs_scaled / scale;
	int frac = abs_scaled % scale;
	if (decimals == 1)
		snprintf(buf, buf_size, "%s%d.%01d", sign, whole, frac);
	else
		snprintf(buf, buf_size, "%s%d.%02d", sign, whole, frac);
}

static bool json_get_payload_int(const char *s, const char *subkey, int *val)
{
	const char *p = json_find_value(s, "payload");
	if (!p) return false;
	const char *q = json_find_value(p, subkey);
	if (!q) return false;
	if (*q == '"') q++;
	*val = atoi(q);
	return true;
}

static bool json_get_payload_string(const char *s, const char *subkey,
				    char *val, int val_size)
{
	const char *p = json_find_value(s, "payload");
	if (!p) return false;
	const char *q = json_find_value(p, subkey);
	if (!q || *q != '"') return false;
	q++;
	int i;
	for (i = 0; i < val_size - 1 && *q && *q != '"'; i++, q++)
		val[i] = *q;
	val[i] = '\0';
	return true;
}

static cmd_type_t str_to_cmd(const char *s)
{
	if (strcmp(s, "heartbeat") == 0)  return CMD_HEARTBEAT;
	if (strcmp(s, "enable") == 0)     return CMD_ENABLE;
	if (strcmp(s, "disable") == 0)    return CMD_DISABLE;
	if (strcmp(s, "estop") == 0)      return CMD_ESTOP;
	if (strcmp(s, "jog_start") == 0)  return CMD_JOG_START;
	if (strcmp(s, "jog_stop") == 0)   return CMD_JOG_STOP;
	if (strcmp(s, "sdo_read") == 0)   return CMD_SDO_READ;
	if (strcmp(s, "sdo_write") == 0)  return CMD_SDO_WRITE;
	if (strcmp(s, "ota_start") == 0)  return CMD_OTA_START;
	if (strcmp(s, "ota_chunk") == 0)  return CMD_OTA_CHUNK;
	if (strcmp(s, "ota_verify") == 0) return CMD_OTA_VERIFY;
	if (strcmp(s, "ota_flash") == 0)  return CMD_OTA_FLASH;
	if (strcmp(s, "set_speed") == 0)  return CMD_SET_SPEED;
	if (strcmp(s, "move_position") == 0) return CMD_MOVE_POSITION;
	return CMD_UNKNOWN;
}

bool cmd_json_parse(const char *json_str, int len, parsed_cmd_t *out)
{
	if (!json_str || len <= 0 || !out) return false;

	memset(out, 0, sizeof(*out));
	out->node = 0;
	out->direction[0] = 'c';
	out->direction[1] = 'w';
	out->direction[2] = '\0';
	out->speed = 50000;

	const char *brace = strchr(json_str, '{');
	if (!brace) return false;

	char cmd_str[32];
	if (!json_get_string(brace, "cmd", cmd_str, sizeof(cmd_str)))
		return false;
	out->cmd = str_to_cmd(cmd_str);

	json_get_int(brace, "seq", &out->seq);

	switch (out->cmd) {
	case CMD_HEARTBEAT:
		json_get_payload_int(brace, "node", &out->node);
		break;
	case CMD_ENABLE:
	case CMD_DISABLE:
	case CMD_JOG_STOP:
	case CMD_OTA_FLASH:
		json_get_payload_int(brace, "node", &out->node);
		break;
	case CMD_SET_SPEED:
		json_get_payload_int(brace, "node", &out->node);
		json_get_payload_int(brace, "speed", &out->speed);
		break;
	case CMD_MOVE_POSITION:
		json_get_payload_int(brace, "node", &out->node);
		json_get_payload_int(brace, "position", &out->position);
		json_get_payload_int(brace, "speed", &out->speed);
		break;
	case CMD_JOG_START:
		json_get_payload_int(brace, "node", &out->node);
		json_get_payload_string(brace, "direction", out->direction,
					sizeof(out->direction));
		json_get_payload_int(brace, "speed", &out->speed);
		break;
	case CMD_SDO_READ:
		json_get_payload_int(brace, "node", &out->node);
		json_get_payload_int(brace, "index", &out->index);
		json_get_payload_int(brace, "sub", &out->sub);
		break;
	case CMD_SDO_WRITE:
		json_get_payload_int(brace, "node", &out->node);
		json_get_payload_int(brace, "index", &out->index);
		json_get_payload_int(brace, "sub", &out->sub);
		json_get_payload_int(brace, "data", &out->data);
		break;
	case CMD_OTA_START:
		json_get_payload_int(brace, "size", &out->ota_size);
		json_get_payload_string(brace, "md5", out->md5, sizeof(out->md5));
		break;
	case CMD_OTA_CHUNK:
		json_get_payload_int(brace, "offset", &out->ota_offset);
		break;
	default:
		break;
	}

	return true;
}

int json_build_ack(char *buf, int buf_size, int seq,
		   const char *status, const char *msg, int node)
{
	return snprintf(buf, buf_size,
		"{\"cmd\":\"ack\",\"seq\":%d,\"ts\":0,"
		"\"payload\":{\"status\":\"%s\",\"msg\":\"%s\",\"node\":%d}}",
		seq, status, msg, node);
}

int json_build_motor_status(char *buf, int buf_size,
			    float current, float voltage,
			    int speed, float position, float torque,
			    uint16_t drive_status_word, bool drive_fault,
			    bool estop_latched, const char *display_status,
			    uint32_t valid_mask, uint32_t fresh_mask, int mode,
			    bool alive, int wdg_ms)
{
	char current_s[16], voltage_s[16], position_s[16], torque_s[16];

	format_fixed(current_s, sizeof(current_s), current, 2);
	format_fixed(voltage_s, sizeof(voltage_s), voltage, 1);
	format_fixed(position_s, sizeof(position_s), position, 1);
	format_fixed(torque_s, sizeof(torque_s), torque, 2);

	return snprintf(buf, buf_size,
		"{\"cmd\":\"motor_status\",\"seq\":0,\"ts\":0,"
		"\"payload\":{"
		"\"current\":%s,\"voltage\":%s,"
		"\"speed\":%d,\"position\":%s,\"torque\":%s,"
		"\"status_word\":%u,\"fault\":%d,"
		"\"drive_status_word\":%u,\"drive_fault\":%s,"
		"\"estop_latched\":%s,\"display_status\":\"%s\","
		"\"valid_mask\":%u,\"fresh_mask\":%u,\"mode\":%d,"
		"\"alive\":%s,\"wdg_ms\":%d"
		"}}",
		current_s, voltage_s, speed, position_s, torque_s,
		drive_status_word, drive_fault ? 1 : 0,
		drive_status_word, drive_fault ? "true" : "false",
		estop_latched ? "true" : "false", display_status,
		valid_mask, fresh_mask, mode,
		alive ? "true" : "false", wdg_ms);
}

int json_build_can_log(char *buf, int buf_size, int can_id,
		       const uint8_t *data, int dlc)
{
	char data_str[64];
	int pos = 0;
	for (int i = 0; i < dlc && i < 8; i++) {
		pos += snprintf(data_str + pos, sizeof(data_str) - pos,
				"%s%02X", (i > 0 ? " " : ""), data[i]);
	}

	return snprintf(buf, buf_size,
		"{\"cmd\":\"can_log\",\"payload\":{"
		"\"id\":\"0x%X\",\"data\":\"%s\",\"dlc\":%d"
		"}}",
		can_id, data_str, dlc);
}
```

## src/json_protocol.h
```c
/*
 * json_protocol.h - JSON 协议解析与构建
 */

#pragma once

#include <stdint.h>
#include <stdbool.h>
#include <stddef.h>

typedef enum {
	CMD_UNKNOWN = 0,
	CMD_HEARTBEAT,
	CMD_ENABLE,
	CMD_DISABLE,
	CMD_ESTOP,
	CMD_JOG_START,
	CMD_JOG_STOP,
	CMD_SDO_READ,
	CMD_SDO_WRITE,
	CMD_OTA_START,
	CMD_OTA_CHUNK,
	CMD_OTA_VERIFY,
	CMD_OTA_FLASH,
	CMD_SET_SPEED,
	CMD_MOVE_POSITION,
} cmd_type_t;

typedef struct {
	cmd_type_t cmd;
	int seq;
	int node;
	char direction[4];
	int speed;
	int position;
	int index;
	int sub;
	int data;
	int ota_size;
	char md5[33];
	int ota_offset;
} parsed_cmd_t;

bool cmd_json_parse(const char *json_str, int len, parsed_cmd_t *out);

int json_build_ack(char *buf, int buf_size, int seq,
		   const char *status, const char *msg, int node);

int json_build_motor_status(char *buf, int buf_size,
			    float current, float voltage,
			    int speed, float position, float torque,
			    uint16_t drive_status_word, bool drive_fault,
			    bool estop_latched, const char *display_status,
			    uint32_t valid_mask, uint32_t fresh_mask, int mode,
			    bool alive, int wdg_ms);

int json_build_can_log(char *buf, int buf_size, int can_id,
		       const uint8_t *data, int dlc);
```

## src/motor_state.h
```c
/*
 * motor_state.h - 共享电机状态 + 内部标志位
 *
 * 所有模块 #include 此文件即可访问电机数据，避免散落在 main.c 中。
 */

#pragma once

#include <stdint.h>
#include <stdbool.h>

#define DEFAULT_NODE 2

enum motor_field {
	MOTOR_FIELD_SPEED = 0,
	MOTOR_FIELD_POSITION,
	MOTOR_FIELD_CURRENT,
	MOTOR_FIELD_VOLTAGE,
	MOTOR_FIELD_TORQUE,
	MOTOR_FIELD_STATUS,
	MOTOR_FIELD_COUNT,
};

#define MOTOR_FIELD_BIT(field) (1U << (field))

/* ---- 电机实时数据（由 SDO 轮询刷新） ---- */
struct motor_state {
	float current;
	float voltage;
	int32_t speed;
	int32_t position;
	float torque;
	uint16_t drive_status_word;
	bool drive_fault;
	bool estop_latched;
	int8_t mode;
	bool alive;
	uint32_t valid_mask;
	uint32_t fresh_mask;
	int64_t updated_ms[MOTOR_FIELD_COUNT];
};

extern struct motor_state g_motor;
extern bool g_motor_enabled;
extern bool g_profile_configured;
extern int32_t g_target_speed;
extern uint8_t g_active_node;
```

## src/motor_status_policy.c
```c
#include "motor_status_policy.h"

bool motor_status_word_has_fault(uint16_t status_word)
{
	return (status_word & 0x0008U) != 0U;
}

bool motor_estop_should_latch(int command_result)
{
	return command_result == 0;
}

enum motor_display_status motor_display_status_resolve(bool alive,
						       bool status_fresh,
						       bool drive_fault,
						       bool estop_latched)
{
	if (estop_latched) {
		return MOTOR_DISPLAY_ESTOP;
	}
	if (!alive) {
		return MOTOR_DISPLAY_OFFLINE;
	}
	if (!status_fresh) {
		return MOTOR_DISPLAY_STALE;
	}
	if (drive_fault) {
		return MOTOR_DISPLAY_DRIVE_FAULT;
	}
	return MOTOR_DISPLAY_READY;
}

const char *motor_display_status_name(enum motor_display_status status)
{
	switch (status) {
	case MOTOR_DISPLAY_ESTOP:
		return "estop";
	case MOTOR_DISPLAY_DRIVE_FAULT:
		return "drive_fault";
	case MOTOR_DISPLAY_READY:
		return "ready";
	case MOTOR_DISPLAY_STALE:
		return "stale";
	case MOTOR_DISPLAY_OFFLINE:
	default:
		return "offline";
	}
}
```
